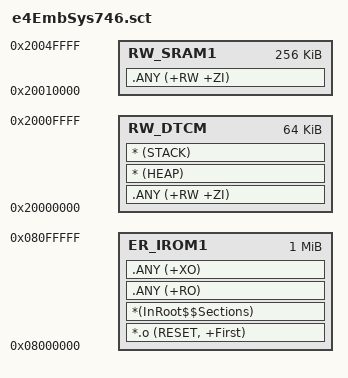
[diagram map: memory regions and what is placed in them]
; *************************************************************
; *** ETTI 4 Scatter-File for STM32F746/STM32F756
; *************************************************************

LR_IROM1 0x08000000 0x00100000  {    ; load region (1 MB)
  ER_IROM1 0x08000000 0x00100000  {  ; load address = execution address
    *.o (RESET, +First)
    *(InRoot$$Sections)
    .ANY (+RO)
    .ANY (+XO)
  }
; *************************************************************
; *** DTCM with Event Recorder
; *************************************************************
;  RW_DTCM 0x20000000 0x0000F800 {    ; 62 kB
;    .ANY (+RW +ZI)                   ; RW data
;    * (ETTI4dmaVar)                  ; Use for DMA Data uncached
;    * (HEAP)                         ; Heap
;    * (STACK)                        ; Stack
;  }
;  RW_DTCM_NOINIT 0x2000F800 UNINIT 0x00000800 { ; 2 kB
;    EventRecorder.o (+ZI)                       ; EventRecorder data
;  }
 
; *************************************************************
; *** DTCM without Event Recorder
; ************************************************************* 
  RW_DTCM 0x20000000 0x00010000 {    ; 64 kB
    .ANY (+RW +ZI)                   ; RW data
;   * (ETTI4dmaVar)                  ; Use for DMA Data uncached
    * (HEAP)                         ; Heap
    * (STACK)                        ; Stack
  }

; *************************************************************
; *** SRAM1 without Network driver
; ************************************************************* 
  RW_SRAM1 0x20010000 0x000040000 {  ; 256 kB
    .ANY (+RW +ZI)                   ; RW data
  }
; *************************************************************
; *** SRAM1 with Network driver
; ************************************************************* 
;  RW_SRAM1 0x20010000 0x00003C000 {  ; 240 kB
;    .ANY (+RW +ZI)                   ; RW data
;  }    
}
